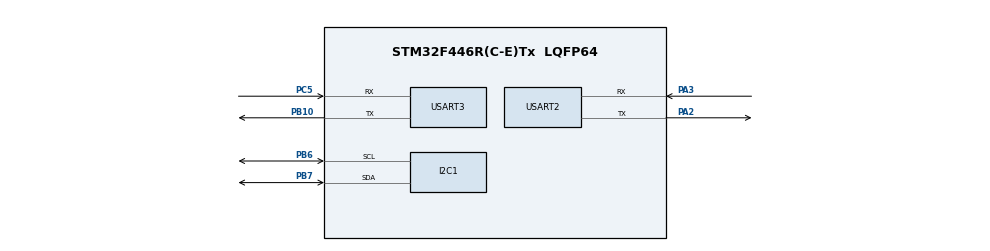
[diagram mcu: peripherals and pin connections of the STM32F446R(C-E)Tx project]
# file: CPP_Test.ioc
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Mcu.Family=STM32F4
RCC.CortexFreq_Value=16000000
PB10.Mode=Asynchronous
PC5.Mode=Asynchronous
ProjectManager.StackSize=0x400
PA3.Mode=Asynchronous
ProjectManager.TargetToolchain=STM32CubeIDE
PB6.Signal=I2C1_SCL
PB6.Mode=I2C
RCC.USBFreq_Value=96000000
PB10.Signal=USART3_TX
board=custom
RCC.VCOOutputFreq_Value=192000000
PB7.Signal=I2C1_SDA
Mcu.Name=STM32F446R(C-E)Tx
PA2.Signal=USART2_TX
Mcu.Package=LQFP64
USART2.VirtualMode=VM_ASYNC
USART3.VirtualMode=VM_ASYNC
PB7.Mode=I2C
ProjectManager.HeapSize=0x200
NVIC.PriorityGroup=NVIC_PRIORITYGROUP_4
PA2.Mode=Asynchronous
PC5.Signal=USART3_RX
PA3.Signal=USART2_RX

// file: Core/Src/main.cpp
/* USER CODE BEGIN Header */
/**
  ******************************************************************************
  * @file           : main.c
  * @brief          : Main program body
  ******************************************************************************
  * @attention
  *
  * <h2><center>&copy; Copyright (c) 2021 STMicroelectronics.
  * All rights reserved.</center></h2>
  *
  * This software component is licensed by ST under BSD 3-Clause license,
  * the "License"; You may not use this file except in compliance with the
  * License. You may obtain a copy of the License at:
  *                        opensource.org/licenses/BSD-3-Clause
  *
  * dmc 4/4/2021: Portions reused from:
  *   https://shawnhymel.com/1873/how-to-use-printf-on-stm32/
  *   https://shawnhymel.com/1941/how-to-use-c-with-stm32cubeide/
  *   https://isocpp.org/wiki/faq/mixing-c-and-cpp#call-c
  *   Carmine Noviello, "Mastering STM32" found at
  *       https://leanpub.com/mastering-stm32
  ******************************************************************************
  */
/* USER CODE END Header */
#include "main.h"

/* USER CODE BEGIN Includes */
// First, c++ includes
#include<iostream>
#include<string>
#include<vector>
#include<algorithm>
#include<cmath>

// Second, inclluds from legacy translation units.
extern "C" {
#include <stdio.h>
#include "retarget.h"
}
/* USER CODE END Includes */

I2C_HandleTypeDef hi2c1;
UART_HandleTypeDef huart2;
UART_HandleTypeDef huart3;

void SystemClock_Config(void);
static void MX_GPIO_Init(void);
static void MX_USART2_UART_Init(void);
static void MX_USART3_UART_Init(void);
static void MX_I2C1_Init(void);

int main(void)
{

  /* MCU Configuration--------------------------------------------------------*/

  /* Reset of all peripherals, Initializes the Flash interface and the Systick. */
  HAL_Init();

  /* Configure the system clock */
  SystemClock_Config();

  /* Initialize all configured peripherals */
  MX_GPIO_Init();
  MX_USART2_UART_Init();
  MX_USART3_UART_Init();
  MX_I2C1_Init();
  /* USER CODE BEGIN 2 */
  RetargetInit(&huart3);
  /* USER CODE END 2 */

  /* Infinite loop */
  while (1)
  {
	printf("Test from c++ and printf\n\r");
	std::cout << "Test from c++ and cout\n\r";
	HAL_Delay(100);
  }
}

void SystemClock_Config(void)
{
  RCC_OscInitTypeDef RCC_OscInitStruct = {0};
  RCC_ClkInitTypeDef RCC_ClkInitStruct = {0};

  /** Configure the main internal regulator output voltage
  */
  __HAL_RCC_PWR_CLK_ENABLE();
  __HAL_PWR_VOLTAGESCALING_CONFIG(PWR_REGULATOR_VOLTAGE_SCALE3);
  /** Initializes the RCC Oscillators according to the specified parameters
  * in the RCC_OscInitTypeDef structure.
  */
  RCC_OscInitStruct.OscillatorType = RCC_OSCILLATORTYPE_HSI;
  RCC_OscInitStruct.HSIState = RCC_HSI_ON;
  RCC_OscInitStruct.HSICalibrationValue = RCC_HSICALIBRATION_DEFAULT;
  RCC_OscInitStruct.PLL.PLLState = RCC_PLL_NONE;
  if (HAL_RCC_OscConfig(&RCC_OscInitStruct) != HAL_OK)
  {
    Error_Handler();
  }
  /** Initializes the CPU, AHB and APB buses clocks
  */
  RCC_ClkInitStruct.ClockType = RCC_CLOCKTYPE_HCLK|RCC_CLOCKTYPE_SYSCLK
                              |RCC_CLOCKTYPE_PCLK1|RCC_CLOCKTYPE_PCLK2;
  RCC_ClkInitStruct.SYSCLKSource = RCC_SYSCLKSOURCE_HSI;
  RCC_ClkInitStruct.AHBCLKDivider = RCC_SYSCLK_DIV1;
  RCC_ClkInitStruct.APB1CLKDivider = RCC_HCLK_DIV1;
  RCC_ClkInitStruct.APB2CLKDivider = RCC_HCLK_DIV1;

  if (HAL_RCC_ClockConfig(&RCC_ClkInitStruct, FLASH_LATENCY_0) != HAL_OK)
  {
    Error_Handler();
  }
}

static void MX_I2C1_Init(void)
{

  hi2c1.Instance = I2C1;
  hi2c1.Init.ClockSpeed = 100000;
  hi2c1.Init.DutyCycle = I2C_DUTYCYCLE_2;
  hi2c1.Init.OwnAddress1 = 0;
  hi2c1.Init.AddressingMode = I2C_ADDRESSINGMODE_7BIT;
  hi2c1.Init.DualAddressMode = I2C_DUALADDRESS_DISABLE;
  hi2c1.Init.OwnAddress2 = 0;
  hi2c1.Init.GeneralCallMode = I2C_GENERALCALL_DISABLE;
  hi2c1.Init.NoStretchMode = I2C_NOSTRETCH_DISABLE;
  if (HAL_I2C_Init(&hi2c1) != HAL_OK)
  {
    Error_Handler();
  }

}

static void MX_USART2_UART_Init(void)
{

  huart2.Instance = USART2;
  huart2.Init.BaudRate = 115200;
  huart2.Init.WordLength = UART_WORDLENGTH_8B;
  huart2.Init.StopBits = UART_STOPBITS_1;
  huart2.Init.Parity = UART_PARITY_NONE;
  huart2.Init.Mode = UART_MODE_TX_RX;
  huart2.Init.HwFlowCtl = UART_HWCONTROL_NONE;
  huart2.Init.OverSampling = UART_OVERSAMPLING_16;
  if (HAL_UART_Init(&huart2) != HAL_OK)
  {
    Error_Handler();
  }

}

static void MX_USART3_UART_Init(void)
{

  huart3.Instance = USART3;
  huart3.Init.BaudRate = 115200;
  huart3.Init.WordLength = UART_WORDLENGTH_8B;
  huart3.Init.StopBits = UART_STOPBITS_1;
  huart3.Init.Parity = UART_PARITY_NONE;
  huart3.Init.Mode = UART_MODE_TX_RX;
  huart3.Init.HwFlowCtl = UART_HWCONTROL_NONE;
  huart3.Init.OverSampling = UART_OVERSAMPLING_16;
  if (HAL_UART_Init(&huart3) != HAL_OK)
  {
    Error_Handler();
  }

}

static void MX_GPIO_Init(void)
{

  /* GPIO Ports Clock Enable */
  __HAL_RCC_GPIOA_CLK_ENABLE();
  __HAL_RCC_GPIOC_CLK_ENABLE();
  __HAL_RCC_GPIOB_CLK_ENABLE();

}

void Error_Handler(void)
{
  __disable_irq();
  while (1)
  {
  }
}

/************************ (C) COPYRIGHT STMicroelectronics *****END OF FILE****/
